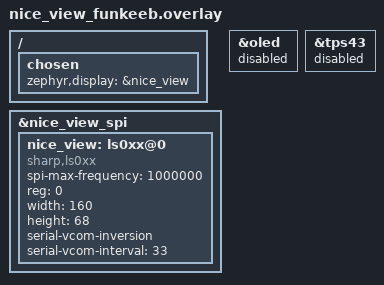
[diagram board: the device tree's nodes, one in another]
/* Keep the working nice!view hardware configuration from current ZMK. */

&nice_view_spi {
    status = "okay";
    nice_view: ls0xx@0 {
        compatible = "sharp,ls0xx";
        spi-max-frequency = <1000000>;
        reg = <0>;
        width = <160>;
        height = <68>;
        serial-vcom-inversion;
        serial-vcom-interval = <33>;
    };
};

/ {
    chosen {
        zephyr,display = &nice_view;
    };
};

/* This is the screen-only right-half alternative. Keep both devices that
 * occupy the Corne display/touchpad area inactive in this variant. */
&oled {
    status = "disabled";
};

&tps43 {
    status = "disabled";
};
